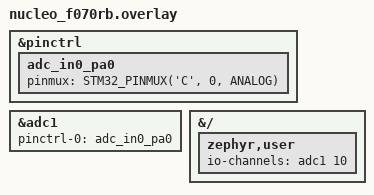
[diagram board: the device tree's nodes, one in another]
/*
 * Copyright (c) 2025 Sudarsan N
 *
 * SPDX-License-Identifier: Apache-2.0
 */

/* stm32f4_disco.overlay */

&pinctrl {
	adc_in0_pa0: adc_in0_pa0 {
		pinmux = <STM32_PINMUX('C', 0, ANALOG)>;

	};
};

&adc1 {
	status = "okay";
	pinctrl-0 = <&adc_in0_pa0>;
	pinctrl-names = "default";
};

&{/} {
	zephyr,user {
		io-channels = <&adc1 10>;
	};
};
